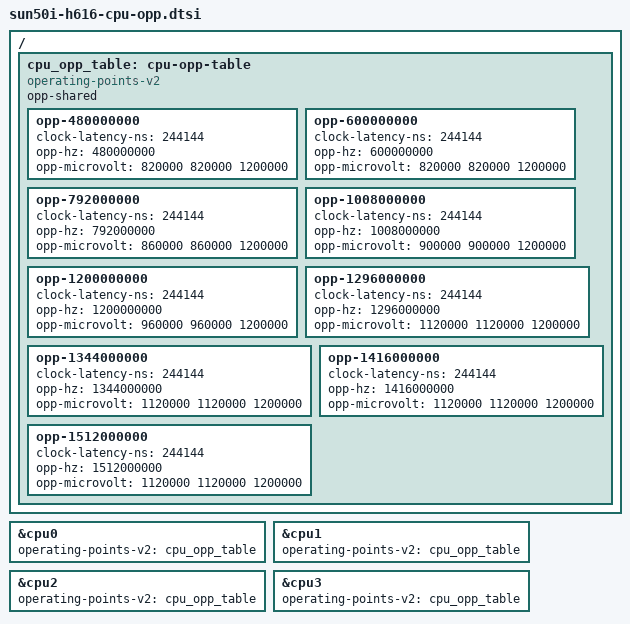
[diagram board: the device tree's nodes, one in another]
// SPDX-License-Identifier: (GPL-2.0+ OR MIT)
// Copyright (C) 2021 Piotr Oniszczuk <piotr.oniszczuk@gmail.com>
/*
  Opi Zero2:bin0  bin1 Tx6s:bin0  bin1
 480000000  820mV  880mV  / 820mV  880mV
 600000000  820mV  880mV  / 820mV  880mV
 792000000  860mV  940mV  / 860mV  940mV
 1008000000 900mV  1020mV / 900mV  1020mV
 1200000000 960mV  1100mV / 960mV  1100mV
 1296000000 1100mV 1100mV / 1100mV 1100mV
 1344000000 1120mV 1120mV / 1120mV 1120mV
 1512000000 1120mV 1120mV / 1120mV 1120mV
*/

 /{
	cpu_opp_table: cpu-opp-table {
		compatible = "operating-points-v2";
		opp-shared;
		opp-480000000 {
			clock-latency-ns = <244144>; /* 8 32k periods */
			opp-hz = /bits/ 64 <480000000>;
		        opp-microvolt = <820000 820000 1200000>;
		};

		opp-600000000 {
			clock-latency-ns = <244144>; /* 8 32k periods */
			opp-hz = /bits/ 64 <600000000>;
			opp-microvolt = <820000 820000 1200000>;
		};

       	opp-792000000 {
			clock-latency-ns = <244144>; /* 8 32k periods */
		        opp-hz = /bits/ 64 <792000000>;
			opp-microvolt = <860000 860000 1200000>;
		};

		opp-1008000000 {
			clock-latency-ns = <244144>; /* 8 32k periods */
			opp-hz = /bits/ 64 <1008000000>;
			opp-microvolt = <900000 900000 1200000>;
		};

		opp-1200000000 {
			clock-latency-ns = <244144>; /* 8 32k periods */
			opp-hz = /bits/ 64 <1200000000>;
		        opp-microvolt = <960000 960000 1200000>;
		};

		opp-1296000000 {
			clock-latency-ns = <244144>; /* 8 32k periods */
			opp-hz = /bits/ 64 <1296000000>;
		        opp-microvolt = <1120000 1120000 1200000>;
		};
	
		opp-1344000000 {
			clock-latency-ns = <244144>; /* 8 32k periods */
			opp-hz = /bits/ 64 <1344000000>;
		        opp-microvolt = <1120000 1120000 1200000>;
		};
	
		opp-1416000000 {
			clock-latency-ns = <244144>; /* 8 32k periods */
			opp-hz = /bits/ 64 <1416000000>;
		         opp-microvolt = <1120000 1120000 1200000>;
		};

		opp-1512000000 {
			clock-latency-ns = <244144>; /* 8 32k periods */
			opp-hz = /bits/ 64 <1512000000>;
		        opp-microvolt = <1120000 1120000 1200000>;
		};
		
		// opp-1608000000 {
		// 	clock-latency-ns = <244144>; /* 8 32k periods */
		// 	opp-hz = /bits/ 64 <1608000000>;
		// 	opp-microvolt = <1160000 1160000 1200000>;
		// };

		// opp-1704000000 {
		// 	clock-latency-ns = <244144>; /* 8 32k periods */
		// 	opp-hz = /bits/ 64 <1704000000>;
		// 	opp-microvolt = <1180000 1180000 1200000>;
		// };

		// opp-1800000000 {
		// 	clock-latency-ns = <244144>; /* 8 32k periods */
		// 	opp-hz = /bits/ 64 <1800000000>;
		// 	opp-microvolt = <1200000 1200000 1200000>;
		// };
												
	};
};

&cpu0 {
	operating-points-v2 = <&cpu_opp_table>;
};

&cpu1 {
	operating-points-v2 = <&cpu_opp_table>;
};

&cpu2 {
	operating-points-v2 = <&cpu_opp_table>;
};

&cpu3 {
	operating-points-v2 = <&cpu_opp_table>;
};
